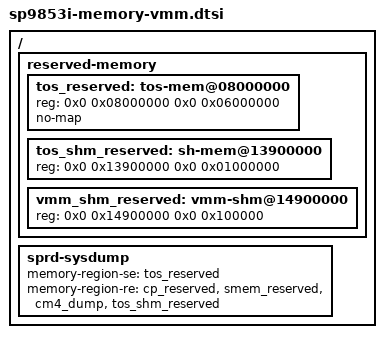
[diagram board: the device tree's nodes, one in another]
/*
 * Spreadtrum SP9861e board common VMM memory DTS file
 *
 * Copyright (C) 2016, Spreadtrum Communications Inc.
 *
 * This file is licensed under a dual GPLv2 or X11 license.
 */
/ {
	reserved-memory {
		tos_reserved: tos-mem@08000000{
			reg = <0x0 0x08000000 0x0 0x06000000>;
			no-map;
		};

		tos_shm_reserved: sh-mem@13900000{
			reg = <0x0 0x13900000 0x0 0x01000000>;
		};

		vmm_shm_reserved: vmm-shm@14900000 {
			reg = <0x0 0x14900000 0x0 0x100000>;
		};

	};

	sprd-sysdump {
		memory-region-se = <&tos_reserved>;
		memory-region-re = <&cp_reserved>, <&smem_reserved>,
				<&cm4_dump>, <&tos_shm_reserved>;
	};
};
